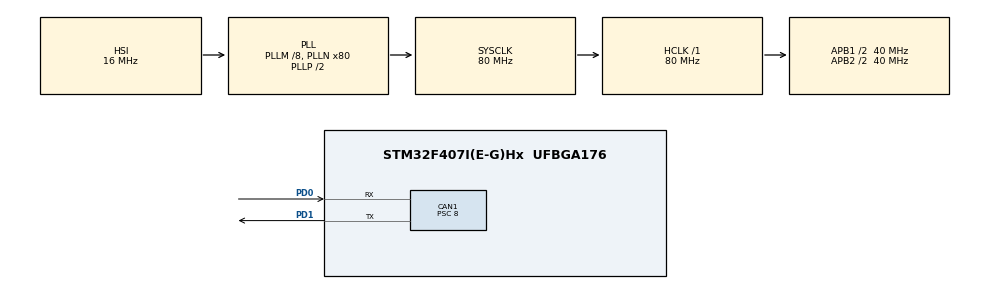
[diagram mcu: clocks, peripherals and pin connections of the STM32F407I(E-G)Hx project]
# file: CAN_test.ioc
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CAN1.BS1=CAN_BS1_2TQ
CAN1.BS2=CAN_BS2_2TQ
CAN1.CalculateBaudRate=1000000
CAN1.CalculateTimeBit=1000
CAN1.CalculateTimeQuantum=200.0
CAN1.Prescaler=8
FREERTOS.Tasks01=CAN_DIAN_JI,0,128,CAN_DJ,Default,NULL,Dynamic,NULL,NULL
Mcu.Family=STM32F4
Mcu.Name=STM32F407I(E-G)Hx
Mcu.Package=UFBGA176
NVIC.CAN1_RX0_IRQn=true\:5\:0\:false\:false\:true\:true\:true\:true\:true
NVIC.PriorityGroup=NVIC_PRIORITYGROUP_4
NVIC.TIM8_TRG_COM_TIM14_IRQn=true\:15\:0\:false\:false\:true\:false\:false\:true\:true
NVIC.TimeBase=TIM8_TRG_COM_TIM14_IRQn
NVIC.TimeBaseIP=TIM14
PA13.Mode=Serial_Wire
PA13.Signal=SYS_JTMS-SWDIO
PA14.Mode=Serial_Wire
PA14.Signal=SYS_JTCK-SWCLK
PD0.Mode=CAN_Activate
PD0.Signal=CAN1_RX
PD1.Mode=CAN_Activate
PD1.Signal=CAN1_TX
PH0-OSC_IN.Mode=HSE-External-Oscillator
PH0-OSC_IN.Signal=RCC_OSC_IN
PH1-OSC_OUT.Mode=HSE-External-Oscillator
PH1-OSC_OUT.Signal=RCC_OSC_OUT
ProjectManager.HeapSize=0x200
ProjectManager.StackSize=0x400
ProjectManager.TargetToolchain=MDK-ARM V5.32
RCC.48MHZClocksFreq_Value=40000000
RCC.AHBFreq_Value=80000000
RCC.APB1CLKDivider=RCC_HCLK_DIV2
RCC.APB1Freq_Value=40000000
RCC.APB1TimFreq_Value=80000000
RCC.APB2CLKDivider=RCC_HCLK_DIV2
RCC.APB2Freq_Value=40000000
RCC.APB2TimFreq_Value=80000000
RCC.CortexFreq_Value=80000000
RCC.HCLKFreq_Value=80000000
RCC.HSE_VALUE=25000000
RCC.HSI_VALUE=16000000
RCC.LSE_VALUE=32768
RCC.PLLM=8
RCC.PLLN=80
RCC.SYSCLKFreq_VALUE=80000000
RCC.SYSCLKSource=RCC_SYSCLKSOURCE_PLLCLK
RCC.VCOOutputFreq_Value=160000000
VP_FREERTOS_VS_CMSIS_V1.Mode=CMSIS_V1
VP_SYS_VS_tim14.Mode=TIM14
board=custom

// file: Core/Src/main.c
/* USER CODE BEGIN Header */
/**
  ******************************************************************************
  * @file           : main.c
  * @brief          : Main program body
  ******************************************************************************
  * @attention
  *
  * Copyright (c) 2025 STMicroelectronics.
  * All rights reserved.
  *
  * This software is licensed under terms that can be found in the LICENSE file
  * in the root directory of this software component.
  * If no LICENSE file comes with this software, it is provided AS-IS.
  *
  ******************************************************************************
  */
/* USER CODE END Header */
#include "main.h"
#include "cmsis_os.h"
#include "can.h"
#include "gpio.h"

/* USER CODE BEGIN Includes */
#include "GM6020.h"
#include "PID.h"
/* USER CODE END Includes */

void SystemClock_Config(void);
void MX_FREERTOS_Init(void);

/* USER CODE BEGIN 0 */
   uint8_t data[8] = {0};
   GM6020_Statu GM_Statu[4];
   PID_Data Speed_PID_Data;
/* USER CODE END 0 */

int main(void)
{

  /* MCU Configuration--------------------------------------------------------*/

  /* Reset of all peripherals, Initializes the Flash interface and the Systick. */
  HAL_Init();

  /* Configure the system clock */
  SystemClock_Config();

  /* Initialize all configured peripherals */
  MX_GPIO_Init();
  MX_CAN1_Init();
  /* USER CODE BEGIN 2 */
  //HAL_CAN_Init(&hcan1);
  //HAL_CAN_Start(&hcan1);
  /* USER CODE END 2 */

  /* Call init function for freertos objects (in cmsis_os2.c) */
  MX_FREERTOS_Init();

  /* Start scheduler */
  osKernelStart();

  /* We should never get here as control is now taken by the scheduler */

  /* Infinite loop */
  while (1)
  {

  }
}

void SystemClock_Config(void)
{
  RCC_OscInitTypeDef RCC_OscInitStruct = {0};
  RCC_ClkInitTypeDef RCC_ClkInitStruct = {0};

  /** Configure the main internal regulator output voltage
  */
  __HAL_RCC_PWR_CLK_ENABLE();
  __HAL_PWR_VOLTAGESCALING_CONFIG(PWR_REGULATOR_VOLTAGE_SCALE1);

  /** Initializes the RCC Oscillators according to the specified parameters
  * in the RCC_OscInitTypeDef structure.
  */
  RCC_OscInitStruct.OscillatorType = RCC_OSCILLATORTYPE_HSI;
  RCC_OscInitStruct.HSIState = RCC_HSI_ON;
  RCC_OscInitStruct.HSICalibrationValue = RCC_HSICALIBRATION_DEFAULT;
  RCC_OscInitStruct.PLL.PLLState = RCC_PLL_ON;
  RCC_OscInitStruct.PLL.PLLSource = RCC_PLLSOURCE_HSI;
  RCC_OscInitStruct.PLL.PLLM = 8;
  RCC_OscInitStruct.PLL.PLLN = 80;
  RCC_OscInitStruct.PLL.PLLP = RCC_PLLP_DIV2;
  RCC_OscInitStruct.PLL.PLLQ = 4;
  if (HAL_RCC_OscConfig(&RCC_OscInitStruct) != HAL_OK)
  {
    Error_Handler();
  }

  /** Initializes the CPU, AHB and APB buses clocks
  */
  RCC_ClkInitStruct.ClockType = RCC_CLOCKTYPE_HCLK|RCC_CLOCKTYPE_SYSCLK
                              |RCC_CLOCKTYPE_PCLK1|RCC_CLOCKTYPE_PCLK2;
  RCC_ClkInitStruct.SYSCLKSource = RCC_SYSCLKSOURCE_PLLCLK;
  RCC_ClkInitStruct.AHBCLKDivider = RCC_SYSCLK_DIV1;
  RCC_ClkInitStruct.APB1CLKDivider = RCC_HCLK_DIV2;
  RCC_ClkInitStruct.APB2CLKDivider = RCC_HCLK_DIV2;

  if (HAL_RCC_ClockConfig(&RCC_ClkInitStruct, FLASH_LATENCY_2) != HAL_OK)
  {
    Error_Handler();
  }
}

void HAL_TIM_PeriodElapsedCallback(TIM_HandleTypeDef *htim)
{
  if (htim->Instance == TIM14) {
    HAL_IncTick();
  }
}

void Error_Handler(void)
{
  __disable_irq();
  while (1)
  {
  }
}

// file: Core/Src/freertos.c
/* USER CODE BEGIN Header */
/**
  ******************************************************************************
  * File Name          : freertos.c
  * Description        : Code for freertos applications
  ******************************************************************************
  * @attention
  *
  * Copyright (c) 2025 STMicroelectronics.
  * All rights reserved.
  *
  * This software is licensed under terms that can be found in the LICENSE file
  * in the root directory of this software component.
  * If no LICENSE file comes with this software, it is provided AS-IS.
  *
  ******************************************************************************
  */
/* USER CODE END Header */

#include "FreeRTOS.h"
#include "task.h"
#include "main.h"
#include "cmsis_os.h"

/* USER CODE BEGIN Includes */
#include "can.h"
#include "GM6020.h"
#include "PID.h"
#include "math.h"
/* USER CODE END Includes */

osThreadId CAN_DIAN_JIHandle;

void CAN_DJ(void const * argument);

void MX_FREERTOS_Init(void); /* (MISRA C 2004 rule 8.1) */

/* GetIdleTaskMemory prototype (linked to static allocation support) */
void vApplicationGetIdleTaskMemory( StaticTask_t **ppxIdleTaskTCBBuffer, StackType_t **ppxIdleTaskStackBuffer, uint32_t *pulIdleTaskStackSize );

/* USER CODE BEGIN GET_IDLE_TASK_MEMORY */
static StaticTask_t xIdleTaskTCBBuffer;
static StackType_t xIdleStack[configMINIMAL_STACK_SIZE];

void vApplicationGetIdleTaskMemory( StaticTask_t **ppxIdleTaskTCBBuffer, StackType_t **ppxIdleTaskStackBuffer, uint32_t *pulIdleTaskStackSize )
{
  *ppxIdleTaskTCBBuffer = &xIdleTaskTCBBuffer;
  *ppxIdleTaskStackBuffer = &xIdleStack[0];
  *pulIdleTaskStackSize = configMINIMAL_STACK_SIZE;
  /* place for user code */
}
/* USER CODE END GET_IDLE_TASK_MEMORY */

void MX_FREERTOS_Init(void) {

  /* Create the thread(s) */
  /* definition and creation of CAN_DIAN_JI */
  osThreadDef(CAN_DIAN_JI, CAN_DJ, osPriorityNormal, 0, 128);
  CAN_DIAN_JIHandle = osThreadCreate(osThread(CAN_DIAN_JI), NULL);

}

void CAN_DJ(void const * argument)
{
  /* USER CODE BEGIN CAN_DJ */
  /* Infinite loop */
  extern GM6020_Statu GM_Statu[4];
 static int16_t obVoltage[4];//相对值电�?? -15000 ~ +15000
//test:
  obVoltage[0] = 0;
  //速度环
  static float TargetSpeed = 0;//rpm:每分钟转速
	PID_Data PID_Speed;
/*
  PID_Speed.Kp = 5;
  PID_Speed.Ki = 0.0001;
	PID_Speed.Kd = 13;
  PID_Speed.errPlus = 0;
  PID_Speed.LastTime = 0;
  PID_Speed.LastData = 0;
  PID_Speed.Limit_Max = 1000;
  PID_Speed.Limit_Min = -1000;
  PID_Speed.Put_Max =  15000;
  PID_Speed.Put_Min = -15000;
*/
  PID_Init(&PID_Speed,5,0.0001,13,1000,-1000,15000,-15000);

  //位置环
  static float TargetAngle = 0; //目标角度(单位°)
  static int16_t MechanicalAngle =  0 ;
  PID_Data PID_Angle;
/*
  PID_Angle.Kp = 0.25;
  PID_Angle.Ki = 0;
  PID_Angle.Kd = 0;
  PID_Angle.errPlus = 0;
  PID_Angle.LastTime = 0;
  PID_Angle.LastData = 0;
  PID_Angle.Limit_Max = 10000;
  PID_Angle.Limit_Min = -10000;
  PID_Angle.Put_Max = 300;
  PID_Angle.Put_Min = -300;
*/
	PID_Init(&PID_Angle,0.25,0,0,10000,-10000,300,-300);

  for(;;)
  {
    //测试
    TargetAngle = (180 * sin(2 * 3.14f * HAL_GetTick() / 1000.0f ) + 180);

    if(TargetAngle < 0)TargetAngle += 360;
    MechanicalAngle = TargetAngle * 8191 / 360 ;
    //过零保护
    // 改进的过零保护
    int32_t error_mech = MechanicalAngle - GM_Statu[0].Mechanical_Angle;
    if(error_mech > 4096) {
            error_mech -= 8191;
    }
     else if(error_mech < -4096) {
              error_mech += 8191;
    }
    float corrected_target = GM_Statu[0].Mechanical_Angle + error_mech;
// 使用修正后的误差进行计算
    //if(TargetAngle == 0)corrected_target = 5;
    TargetSpeed = PID_Set(&PID_Angle,GM_Statu[0].Mechanical_Angle,corrected_target);
    obVoltage[0] += PID_Set(&PID_Speed,GM_Statu[0].Speed_rpm,TargetSpeed);
    GM6020_SetVoltageAll(obVoltage);
    osDelay(1);
  }
  /* USER CODE END CAN_DJ */
}
